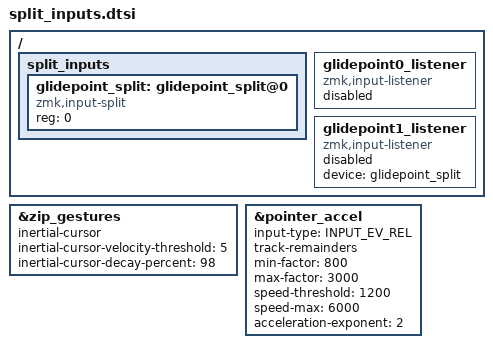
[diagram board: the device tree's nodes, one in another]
#include <input/processors.dtsi>
#include <dt-bindings/zmk/input_transform.h>
#include <behaviors/input_gestures_accel.dtsi>
#include <behaviors/input_processor_gestures.dtsi>

&zip_gestures {
    // https://github.com/halfdane/zmk-input-gestures

    // Activate gestures and change their configuration as you see fit.
    // for details, see the section below that describes all gestures and
    // their configuration options.

    // This will create a mouseclick if your touch is short enough.
    // if you're running in relative mode and don't use no-taps, this might
    // result in duplicate taps

    //tap-detection;
    //tap-timout-ms=<120>;

    inertial-cursor;
    inertial-cursor-velocity-threshold=<5>;
    inertial-cursor-decay-percent=<98>;
};

&pointer_accel {
    input-type = <INPUT_EV_REL>;  // For relative input devices
    track-remainders;             // Accumulate fractional movements
    min-factor = <800>;          // 0.8x at very slow speeds
    max-factor = <3000>;         // 3.0x at fast speeds
    speed-threshold = <1200>;     // 1200 counts/sec for 1x
    speed-max = <6000>;          // 6000 counts/sec for max accel
    acceleration-exponent = <2>;  // Quadratic acceleration curve
};

/ {
    split_inputs {
        #address-cells = <1>;
        #size-cells = <0>;

        glidepoint_split: glidepoint_split@0 {
            compatible = "zmk,input-split";
            reg = <0>;
        };
    };

    glidepoint0_listener: glidepoint0_listener {
        compatible = "zmk,input-listener";
        status = "disabled";

    };

    glidepoint1_listener: glidepoint1_listener {
        compatible = "zmk,input-listener";
        status = "disabled";
        device = <&glidepoint_split>;
    };
};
